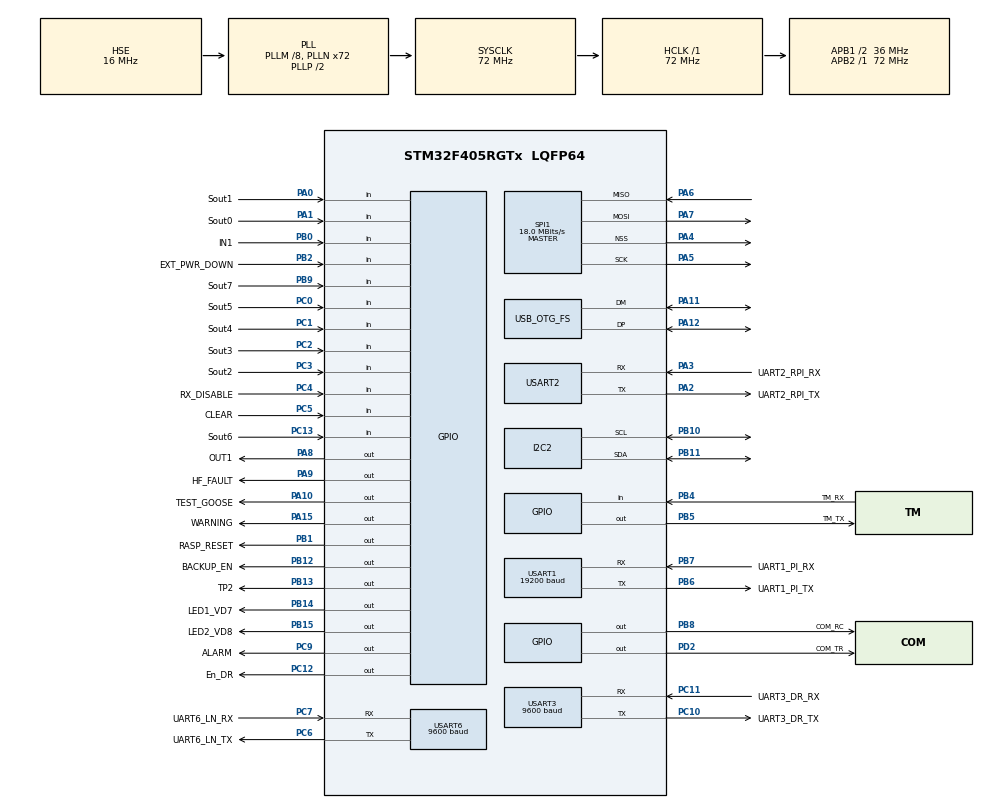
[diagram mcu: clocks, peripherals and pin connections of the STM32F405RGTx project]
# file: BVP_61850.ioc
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I2C2.DualAddressMode=I2C_DUALADDRESS_ENABLE
I2C2.I2C_Mode=I2C_Standard
I2C2.OwnAddress=0x3D
I2C2.OwnAddress2=0x3E
Mcu.Family=STM32F4
Mcu.Name=STM32F405RGTx
Mcu.Package=LQFP64
NVIC.I2C2_ER_IRQn=true\:0\:0\:false\:false\:true\:true\:true
NVIC.I2C2_EV_IRQn=true\:0\:0\:false\:false\:true\:true\:true
NVIC.OTG_FS_IRQn=true\:0\:0\:false\:false\:true\:false\:true
NVIC.PriorityGroup=NVIC_PRIORITYGROUP_4
NVIC.TIM6_DAC_IRQn=true\:0\:0\:false\:false\:true\:true\:true
NVIC.TIM7_IRQn=true\:0\:0\:false\:false\:true\:true\:true
NVIC.USART1_IRQn=true\:0\:0\:false\:false\:true\:true\:true
NVIC.USART2_IRQn=true\:0\:0\:false\:false\:true\:true\:true
NVIC.USART3_IRQn=true\:0\:0\:false\:false\:true\:true\:true
NVIC.USART6_IRQn=true\:0\:0\:false\:false\:true\:true\:true
PA0-WKUP.GPIO_Label=Sout1
PA0-WKUP.GPIO_PuPd=GPIO_PULLUP
PA0-WKUP.Signal=GPIO_Input
PA1.GPIO_Label=Sout0
PA1.GPIO_PuPd=GPIO_PULLUP
PA1.Signal=GPIO_Input
PA10.GPIO_Label=TEST_GOOSE
PA10.Signal=GPIO_Output
PA11.Mode=Device_Only
PA11.Signal=USB_OTG_FS_DM
PA12.Mode=Device_Only
PA12.Signal=USB_OTG_FS_DP
PA13.Mode=Trace_Asynchronous_SW
PA13.Signal=SYS_JTMS-SWDIO
PA14.Mode=Trace_Asynchronous_SW
PA14.Signal=SYS_JTCK-SWCLK
PA15.GPIO_Label=WARNING
PA15.Signal=GPIO_Output
PA2.GPIO_Label=UART2_RPI_TX
PA2.Mode=Asynchronous
PA2.Signal=USART2_TX
PA3.GPIO_Label=UART2_RPI_RX
PA3.Mode=Asynchronous
PA3.Signal=USART2_RX
PA4.Mode=NSS_Signal_Hard_Output
PA4.Signal=SPI1_NSS
PA5.Mode=Full_Duplex_Master
PA5.Signal=SPI1_SCK
PA6.Mode=Full_Duplex_Master
PA6.Signal=SPI1_MISO
PA7.Mode=Full_Duplex_Master
PA7.Signal=SPI1_MOSI
PA8.GPIO_Label=OUT1
PA8.Signal=GPIO_Output
PA9.GPIO_Label=HF_FAULT
PA9.Signal=GPIO_Output
PB0.GPIO_Label=IN1
PB0.Signal=GPIO_Input
PB1.GPIO_Label=RASP_RESET
PB1.PinState=GPIO_PIN_SET
PB1.Signal=GPIO_Output
PB10.Mode=I2C
PB10.Signal=I2C2_SCL
PB11.Mode=I2C
PB11.Signal=I2C2_SDA
PB12.GPIO_Label=BACKUP_EN
PB12.GPIO_Speed=GPIO_SPEED_FREQ_HIGH
PB12.Signal=GPIO_Output
PB13.GPIO_Label=TP2
PB13.Signal=GPIO_Output
PB14.GPIO_Label=LED1_VD7
PB14.Signal=GPIO_Output
PB15.GPIO_Label=LED2_VD8
PB15.GPIO_ModeDefaultOutputPP=GPIO_MODE_OUTPUT_OD
PB15.Signal=GPIO_Output
PB2.GPIO_Label=EXT_PWR_DOWN
PB2.GPIO_PuPd=GPIO_PULLUP
PB2.Signal=GPIO_Input
PB3.Mode=Trace_Asynchronous_SW
PB3.Signal=SYS_JTDO-SWO
PB4.GPIO_Label=TM_RX
PB4.Signal=GPIO_Input
PB5.GPIO_Label=TM_TX
PB5.Signal=GPIO_Output
PB6.GPIO_Label=UART1_PI_TX
PB6.Mode=Asynchronous
PB6.Signal=USART1_TX
PB7.GPIO_Label=UART1_PI_RX
PB7.Mode=Asynchronous
PB7.Signal=USART1_RX
PB8.GPIO_Label=COM_RC
PB8.Signal=GPIO_Output
PB9.GPIO_Label=Sout7
PB9.GPIO_PuPd=GPIO_PULLUP
PB9.Signal=GPIO_Input
PC0.GPIO_Label=Sout5
PC0.GPIO_PuPd=GPIO_PULLUP
PC0.Signal=GPIO_Input
PC1.GPIO_Label=Sout4
PC1.GPIO_PuPd=GPIO_PULLUP
PC1.Signal=GPIO_Input
PC10.GPIO_Label=UART3_DR_TX
PC10.Mode=Asynchronous
PC10.Signal=USART3_TX
PC11.GPIO_Label=UART3_DR_RX
PC11.Mode=Asynchronous
PC11.Signal=USART3_RX
PC12.GPIO_Label=En_DR
PC12.Signal=GPIO_Output
PC13-ANTI_TAMP.GPIO_Label=Sout6
PC13-ANTI_TAMP.GPIO_PuPd=GPIO_PULLUP
PC13-ANTI_TAMP.Signal=GPIO_Input
PC2.GPIO_Label=Sout3
PC2.GPIO_PuPd=GPIO_PULLUP
PC2.Signal=GPIO_Input
PC3.GPIO_Label=Sout2
PC3.GPIO_PuPd=GPIO_PULLUP
PC3.Signal=GPIO_Input
PC4.GPIO_Label=RX_DISABLE
PC4.Signal=GPIO_Input
PC5.GPIO_Label=CLEAR
PC5.Signal=GPIO_Input
PC6.GPIO_Label=UART6_LN_TX
PC6.Mode=Asynchronous
PC6.Signal=USART6_TX
PC7.GPIO_Label=UART6_LN_RX
PC7.Mode=Asynchronous
PC7.Signal=USART6_RX
PC9.GPIO_Label=ALARM
PC9.Signal=GPIO_Output
PD2.GPIO_Label=COM_TR
PD2.Signal=GPIO_Output
PH0-OSC_IN.Mode=HSE-External-Oscillator
PH0-OSC_IN.Signal=RCC_OSC_IN
PH1-OSC_OUT.Mode=HSE-External-Oscillator
PH1-OSC_OUT.Signal=RCC_OSC_OUT
ProjectManager.HeapSize=0x4000
ProjectManager.StackSize=0x4000
ProjectManager.TargetToolchain=SW4STM32
RCC.48MHZClocksFreq_Value=48000000
RCC.AHBFreq_Value=72000000
RCC.APB1CLKDivider=RCC_HCLK_DIV2
RCC.APB1Freq_Value=36000000
RCC.APB1TimFreq_Value=72000000
RCC.APB2Freq_Value=72000000
RCC.APB2TimFreq_Value=72000000
RCC.CortexFreq_Value=72000000
RCC.HCLKFreq_Value=72000000
RCC.HSE_VALUE=16000000
RCC.HSI_VALUE=16000000
RCC.LSE_VALUE=32768
RCC.PLLM=8
RCC.PLLN=72
RCC.PLLQ=3
RCC.SYSCLKFreq_VALUE=72000000
RCC.SYSCLKSource=RCC_SYSCLKSOURCE_PLLCLK
RCC.VCOOutputFreq_Value=144000000
SPI1.BaudRatePrescaler=SPI_BAUDRATEPRESCALER_4
SPI1.CalculateBaudRate=18.0 MBits/s
SPI1.Direction=SPI_DIRECTION_2LINES
SPI1.Mode=SPI_MODE_MASTER
SPI1.VirtualNSS=VM_NSSHARD
SPI1.VirtualType=VM_MASTER
TIM6.AutoReloadPreload=TIM_AUTORELOAD_PRELOAD_ENABLE
TIM6.Period=9
TIM6.Prescaler=7199
TIM7.AutoReloadPreload=TIM_AUTORELOAD_PRELOAD_ENABLE
TIM7.Period=9
TIM7.Prescaler=719
USART1.BaudRate=19200
USART1.StopBits=STOPBITS_2
USART1.VirtualMode=VM_ASYNC
USART2.VirtualMode=VM_ASYNC
USART3.BaudRate=9600
USART3.Parity=PARITY_EVEN
USART3.VirtualMode=VM_ASYNC
USART3.WordLength=WORDLENGTH_9B
USART6.BaudRate=9600
USART6.Parity=PARITY_EVEN
USART6.VirtualMode=VM_ASYNC
USART6.WordLength=WORDLENGTH_9B
USB_DEVICE.CLASS_NAME_FS=CDC
USB_DEVICE.VirtualMode-CDC_FS=Cdc
USB_DEVICE.VirtualModeFS=Cdc_FS
USB_OTG_FS.VirtualMode=Device_Only
VP_IWDG_VS_IWDG.Mode=IWDG_Activate
VP_TIM6_VS_ClockSourceINT.Mode=Enable_Timer
VP_TIM7_VS_ClockSourceINT.Mode=Enable_Timer
VP_USB_DEVICE_VS_USB_DEVICE_CDC_FS.Mode=CDC_FS
board=custom

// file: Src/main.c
/* USER CODE BEGIN Header */
/**
 ******************************************************************************
 * @file           : main.c
 * @brief          : Main program body
 ******************************************************************************
 * @attention
 *
 * <h2><center>&copy; Copyright (c) 2020 STMicroelectronics.
 * All rights reserved.</center></h2>
 *
 * This software component is licensed by ST under Ultimate Liberty license
 * SLA0044, the "License"; You may not use this file except in compliance with
 * the License. You may obtain a copy of the License at:
 *                             www.st.com/SLA0044
 *
 ******************************************************************************
 */
/* USER CODE END Header */
#include "main.h"
#include "usb_device.h"

/* USER CODE BEGIN Includes */
#include "wrapper.hpp"
/* USER CODE END Includes */

I2C_HandleTypeDef hi2c2;

IWDG_HandleTypeDef hiwdg;

SPI_HandleTypeDef hspi1;

TIM_HandleTypeDef htim6;
TIM_HandleTypeDef htim7;

UART_HandleTypeDef huart1;
UART_HandleTypeDef huart2;
UART_HandleTypeDef huart3;
UART_HandleTypeDef huart6;

void SystemClock_Config(void);
static void MX_GPIO_Init(void);
static void MX_IWDG_Init(void);
static void MX_SPI1_Init(void);
static void MX_USART1_UART_Init(void);
static void MX_USART2_UART_Init(void);
static void MX_USART3_UART_Init(void);
static void MX_USART6_UART_Init(void);
static void MX_TIM6_Init(void);
static void MX_I2C2_Init(void);
static void MX_TIM7_Init(void);

int main(void)
{

  /* MCU Configuration--------------------------------------------------------*/

  /* Reset of all peripherals, Initializes the Flash interface and the Systick. */
  HAL_Init();

  /* Configure the system clock */
  SystemClock_Config();

  /* Initialize all configured peripherals */
  MX_GPIO_Init();
  MX_IWDG_Init();
  MX_SPI1_Init();
  MX_USART1_UART_Init();
  MX_USART2_UART_Init();
  MX_USART3_UART_Init();
  MX_USART6_UART_Init();
  MX_TIM6_Init();
  MX_USB_DEVICE_Init();
  MX_I2C2_Init();
  MX_TIM7_Init();
  /* USER CODE BEGIN 2 */

  wrapperMainInit();

  /* USER CODE END 2 */

  /* Infinite loop */
  /* USER CODE BEGIN WHILE */
  HAL_TIM_Base_Start_IT(&htim6);
  HAL_TIM_Base_Start_IT(&htim7);

  while (1) {
    /* USER CODE END WHILE */

    /* USER CODE BEGIN 3 */
    wrapperMainLoop();
  }
  /* USER CODE END 3 */
}

void SystemClock_Config(void)
{
  RCC_OscInitTypeDef RCC_OscInitStruct = {0};
  RCC_ClkInitTypeDef RCC_ClkInitStruct = {0};

  /** Configure the main internal regulator output voltage
  */
  __HAL_RCC_PWR_CLK_ENABLE();
  __HAL_PWR_VOLTAGESCALING_CONFIG(PWR_REGULATOR_VOLTAGE_SCALE1);
  /** Initializes the RCC Oscillators according to the specified parameters
  * in the RCC_OscInitTypeDef structure.
  */
  RCC_OscInitStruct.OscillatorType = RCC_OSCILLATORTYPE_LSI|RCC_OSCILLATORTYPE_HSE;
  RCC_OscInitStruct.HSEState = RCC_HSE_ON;
  RCC_OscInitStruct.LSIState = RCC_LSI_ON;
  RCC_OscInitStruct.PLL.PLLState = RCC_PLL_ON;
  RCC_OscInitStruct.PLL.PLLSource = RCC_PLLSOURCE_HSE;
  RCC_OscInitStruct.PLL.PLLM = 8;
  RCC_OscInitStruct.PLL.PLLN = 72;
  RCC_OscInitStruct.PLL.PLLP = RCC_PLLP_DIV2;
  RCC_OscInitStruct.PLL.PLLQ = 3;
  if (HAL_RCC_OscConfig(&RCC_OscInitStruct) != HAL_OK)
  {
    Error_Handler();
  }
  /** Initializes the CPU, AHB and APB buses clocks
  */
  RCC_ClkInitStruct.ClockType = RCC_CLOCKTYPE_HCLK|RCC_CLOCKTYPE_SYSCLK
                              |RCC_CLOCKTYPE_PCLK1|RCC_CLOCKTYPE_PCLK2;
  RCC_ClkInitStruct.SYSCLKSource = RCC_SYSCLKSOURCE_PLLCLK;
  RCC_ClkInitStruct.AHBCLKDivider = RCC_SYSCLK_DIV1;
  RCC_ClkInitStruct.APB1CLKDivider = RCC_HCLK_DIV2;
  RCC_ClkInitStruct.APB2CLKDivider = RCC_HCLK_DIV1;

  if (HAL_RCC_ClockConfig(&RCC_ClkInitStruct, FLASH_LATENCY_2) != HAL_OK)
  {
    Error_Handler();
  }
}

static void MX_I2C2_Init(void)
{

  hi2c2.Instance = I2C2;
  hi2c2.Init.ClockSpeed = 100000;
  hi2c2.Init.DutyCycle = I2C_DUTYCYCLE_2;
  hi2c2.Init.OwnAddress1 = 122;
  hi2c2.Init.AddressingMode = I2C_ADDRESSINGMODE_7BIT;
  hi2c2.Init.DualAddressMode = I2C_DUALADDRESS_ENABLE;
  hi2c2.Init.OwnAddress2 = 124;
  hi2c2.Init.GeneralCallMode = I2C_GENERALCALL_DISABLE;
  hi2c2.Init.NoStretchMode = I2C_NOSTRETCH_DISABLE;
  if (HAL_I2C_Init(&hi2c2) != HAL_OK)
  {
    Error_Handler();
  }

}

static void MX_IWDG_Init(void)
{

  hiwdg.Instance = IWDG;
  hiwdg.Init.Prescaler = IWDG_PRESCALER_4;
  hiwdg.Init.Reload = 4095;
  if (HAL_IWDG_Init(&hiwdg) != HAL_OK)
  {
    Error_Handler();
  }

}

static void MX_SPI1_Init(void)
{

  /* SPI1 parameter configuration*/
  hspi1.Instance = SPI1;
  hspi1.Init.Mode = SPI_MODE_MASTER;
  hspi1.Init.Direction = SPI_DIRECTION_2LINES;
  hspi1.Init.DataSize = SPI_DATASIZE_8BIT;
  hspi1.Init.CLKPolarity = SPI_POLARITY_LOW;
  hspi1.Init.CLKPhase = SPI_PHASE_1EDGE;
  hspi1.Init.NSS = SPI_NSS_HARD_OUTPUT;
  hspi1.Init.BaudRatePrescaler = SPI_BAUDRATEPRESCALER_4;
  hspi1.Init.FirstBit = SPI_FIRSTBIT_MSB;
  hspi1.Init.TIMode = SPI_TIMODE_DISABLE;
  hspi1.Init.CRCCalculation = SPI_CRCCALCULATION_DISABLE;
  hspi1.Init.CRCPolynomial = 10;
  if (HAL_SPI_Init(&hspi1) != HAL_OK)
  {
    Error_Handler();
  }

}

static void MX_TIM6_Init(void)
{

  TIM_MasterConfigTypeDef sMasterConfig = {0};

  htim6.Instance = TIM6;
  htim6.Init.Prescaler = 7199;
  htim6.Init.CounterMode = TIM_COUNTERMODE_UP;
  htim6.Init.Period = 9;
  htim6.Init.AutoReloadPreload = TIM_AUTORELOAD_PRELOAD_ENABLE;
  if (HAL_TIM_Base_Init(&htim6) != HAL_OK)
  {
    Error_Handler();
  }
  sMasterConfig.MasterOutputTrigger = TIM_TRGO_RESET;
  sMasterConfig.MasterSlaveMode = TIM_MASTERSLAVEMODE_DISABLE;
  if (HAL_TIMEx_MasterConfigSynchronization(&htim6, &sMasterConfig) != HAL_OK)
  {
    Error_Handler();
  }

}

static void MX_TIM7_Init(void)
{

  TIM_MasterConfigTypeDef sMasterConfig = {0};

  htim7.Instance = TIM7;
  htim7.Init.Prescaler = 719;
  htim7.Init.CounterMode = TIM_COUNTERMODE_UP;
  htim7.Init.Period = 9;
  htim7.Init.AutoReloadPreload = TIM_AUTORELOAD_PRELOAD_ENABLE;
  if (HAL_TIM_Base_Init(&htim7) != HAL_OK)
  {
    Error_Handler();
  }
  sMasterConfig.MasterOutputTrigger = TIM_TRGO_RESET;
  sMasterConfig.MasterSlaveMode = TIM_MASTERSLAVEMODE_DISABLE;
  if (HAL_TIMEx_MasterConfigSynchronization(&htim7, &sMasterConfig) != HAL_OK)
  {
    Error_Handler();
  }

}

static void MX_USART1_UART_Init(void)
{

  huart1.Instance = USART1;
  huart1.Init.BaudRate = 19200;
  huart1.Init.WordLength = UART_WORDLENGTH_8B;
  huart1.Init.StopBits = UART_STOPBITS_2;
  huart1.Init.Parity = UART_PARITY_NONE;
  huart1.Init.Mode = UART_MODE_TX_RX;
  huart1.Init.HwFlowCtl = UART_HWCONTROL_NONE;
  huart1.Init.OverSampling = UART_OVERSAMPLING_16;
  if (HAL_UART_Init(&huart1) != HAL_OK)
  {
    Error_Handler();
  }

}

static void MX_USART2_UART_Init(void)
{

  huart2.Instance = USART2;
  huart2.Init.BaudRate = 115200;
  huart2.Init.WordLength = UART_WORDLENGTH_8B;
  huart2.Init.StopBits = UART_STOPBITS_1;
  huart2.Init.Parity = UART_PARITY_NONE;
  huart2.Init.Mode = UART_MODE_TX_RX;
  huart2.Init.HwFlowCtl = UART_HWCONTROL_NONE;
  huart2.Init.OverSampling = UART_OVERSAMPLING_16;
  if (HAL_UART_Init(&huart2) != HAL_OK)
  {
    Error_Handler();
  }

}

static void MX_USART3_UART_Init(void)
{

  huart3.Instance = USART3;
  huart3.Init.BaudRate = 9600;
  huart3.Init.WordLength = UART_WORDLENGTH_9B;
  huart3.Init.StopBits = UART_STOPBITS_1;
  huart3.Init.Parity = UART_PARITY_EVEN;
  huart3.Init.Mode = UART_MODE_TX_RX;
  huart3.Init.HwFlowCtl = UART_HWCONTROL_NONE;
  huart3.Init.OverSampling = UART_OVERSAMPLING_16;
  if (HAL_UART_Init(&huart3) != HAL_OK)
  {
    Error_Handler();
  }

}

static void MX_USART6_UART_Init(void)
{

  huart6.Instance = USART6;
  huart6.Init.BaudRate = 9600;
  huart6.Init.WordLength = UART_WORDLENGTH_9B;
  huart6.Init.StopBits = UART_STOPBITS_1;
  huart6.Init.Parity = UART_PARITY_EVEN;
  huart6.Init.Mode = UART_MODE_TX_RX;
  huart6.Init.HwFlowCtl = UART_HWCONTROL_NONE;
  huart6.Init.OverSampling = UART_OVERSAMPLING_16;
  if (HAL_UART_Init(&huart6) != HAL_OK)
  {
    Error_Handler();
  }

}

static void MX_GPIO_Init(void)
{
  GPIO_InitTypeDef GPIO_InitStruct = {0};

  /* GPIO Ports Clock Enable */
  __HAL_RCC_GPIOC_CLK_ENABLE();
  __HAL_RCC_GPIOH_CLK_ENABLE();
  __HAL_RCC_GPIOA_CLK_ENABLE();
  __HAL_RCC_GPIOB_CLK_ENABLE();
  __HAL_RCC_GPIOD_CLK_ENABLE();

  /*Configure GPIO pin Output Level */
  HAL_GPIO_WritePin(RASP_RESET_GPIO_Port, RASP_RESET_Pin, GPIO_PIN_SET);

  /*Configure GPIO pin Output Level */
  HAL_GPIO_WritePin(GPIOB, BACKUP_EN_Pin|TP2_Pin|LED1_VD7_Pin|LED2_VD8_Pin
                          |TM_TX_Pin|COM_RC_Pin, GPIO_PIN_RESET);

  /*Configure GPIO pin Output Level */
  HAL_GPIO_WritePin(GPIOC, ALARM_Pin|En_DR_Pin, GPIO_PIN_RESET);

  /*Configure GPIO pin Output Level */
  HAL_GPIO_WritePin(GPIOA, OUT1_Pin|HF_FAULT_Pin|TEST_GOOSE_Pin|WARNING_Pin, GPIO_PIN_RESET);

  /*Configure GPIO pin Output Level */
  HAL_GPIO_WritePin(COM_TR_GPIO_Port, COM_TR_Pin, GPIO_PIN_RESET);

  /*Configure GPIO pins : Sout6_Pin Sout5_Pin Sout4_Pin Sout3_Pin
                           Sout2_Pin */
  GPIO_InitStruct.Pin = Sout6_Pin|Sout5_Pin|Sout4_Pin|Sout3_Pin
                          |Sout2_Pin;
  GPIO_InitStruct.Mode = GPIO_MODE_INPUT;
  GPIO_InitStruct.Pull = GPIO_PULLUP;
  HAL_GPIO_Init(GPIOC, &GPIO_InitStruct);

  /*Configure GPIO pins : Sout1_Pin Sout0_Pin */
  GPIO_InitStruct.Pin = Sout1_Pin|Sout0_Pin;
  GPIO_InitStruct.Mode = GPIO_MODE_INPUT;
  GPIO_InitStruct.Pull = GPIO_PULLUP;
  HAL_GPIO_Init(GPIOA, &GPIO_InitStruct);

  /*Configure GPIO pins : RX_DISABLE_Pin CLEAR_Pin */
  GPIO_InitStruct.Pin = RX_DISABLE_Pin|CLEAR_Pin;
  GPIO_InitStruct.Mode = GPIO_MODE_INPUT;
  GPIO_InitStruct.Pull = GPIO_NOPULL;
  HAL_GPIO_Init(GPIOC, &GPIO_InitStruct);

  /*Configure GPIO pins : IN1_Pin TM_RX_Pin */
  GPIO_InitStruct.Pin = IN1_Pin|TM_RX_Pin;
  GPIO_InitStruct.Mode = GPIO_MODE_INPUT;
  GPIO_InitStruct.Pull = GPIO_NOPULL;
  HAL_GPIO_Init(GPIOB, &GPIO_InitStruct);

  /*Configure GPIO pins : RASP_RESET_Pin TP2_Pin LED1_VD7_Pin TM_TX_Pin
                           COM_RC_Pin */
  GPIO_InitStruct.Pin = RASP_RESET_Pin|TP2_Pin|LED1_VD7_Pin|TM_TX_Pin
                          |COM_RC_Pin;
  GPIO_InitStruct.Mode = GPIO_MODE_OUTPUT_PP;
  GPIO_InitStruct.Pull = GPIO_NOPULL;
  GPIO_InitStruct.Speed = GPIO_SPEED_FREQ_LOW;
  HAL_GPIO_Init(GPIOB, &GPIO_InitStruct);

  /*Configure GPIO pins : EXT_PWR_DOWN_Pin Sout7_Pin */
  GPIO_InitStruct.Pin = EXT_PWR_DOWN_Pin|Sout7_Pin;
  GPIO_InitStruct.Mode = GPIO_MODE_INPUT;
  GPIO_InitStruct.Pull = GPIO_PULLUP;
  HAL_GPIO_Init(GPIOB, &GPIO_InitStruct);

  /*Configure GPIO pin : BACKUP_EN_Pin */
  GPIO_InitStruct.Pin = BACKUP_EN_Pin;
  GPIO_InitStruct.Mode = GPIO_MODE_OUTPUT_PP;
  GPIO_InitStruct.Pull = GPIO_NOPULL;
  GPIO_InitStruct.Speed = GPIO_SPEED_FREQ_HIGH;
  HAL_GPIO_Init(BACKUP_EN_GPIO_Port, &GPIO_InitStruct);

  /*Configure GPIO pin : LED2_VD8_Pin */
  GPIO_InitStruct.Pin = LED2_VD8_Pin;
  GPIO_InitStruct.Mode = GPIO_MODE_OUTPUT_OD;
  GPIO_InitStruct.Pull = GPIO_NOPULL;
  GPIO_InitStruct.Speed = GPIO_SPEED_FREQ_LOW;
  HAL_GPIO_Init(LED2_VD8_GPIO_Port, &GPIO_InitStruct);

  /*Configure GPIO pins : ALARM_Pin En_DR_Pin */
  GPIO_InitStruct.Pin = ALARM_Pin|En_DR_Pin;
  GPIO_InitStruct.Mode = GPIO_MODE_OUTPUT_PP;
  GPIO_InitStruct.Pull = GPIO_NOPULL;
  GPIO_InitStruct.Speed = GPIO_SPEED_FREQ_LOW;
  HAL_GPIO_Init(GPIOC, &GPIO_InitStruct);

  /*Configure GPIO pins : OUT1_Pin HF_FAULT_Pin TEST_GOOSE_Pin WARNING_Pin */
  GPIO_InitStruct.Pin = OUT1_Pin|HF_FAULT_Pin|TEST_GOOSE_Pin|WARNING_Pin;
  GPIO_InitStruct.Mode = GPIO_MODE_OUTPUT_PP;
  GPIO_InitStruct.Pull = GPIO_NOPULL;
  GPIO_InitStruct.Speed = GPIO_SPEED_FREQ_LOW;
  HAL_GPIO_Init(GPIOA, &GPIO_InitStruct);

  /*Configure GPIO pin : COM_TR_Pin */
  GPIO_InitStruct.Pin = COM_TR_Pin;
  GPIO_InitStruct.Mode = GPIO_MODE_OUTPUT_PP;
  GPIO_InitStruct.Pull = GPIO_NOPULL;
  GPIO_InitStruct.Speed = GPIO_SPEED_FREQ_LOW;
  HAL_GPIO_Init(COM_TR_GPIO_Port, &GPIO_InitStruct);

}

void Error_Handler(void)
{
  /* USER CODE BEGIN Error_Handler_Debug */
  /* User can add his own implementation to report the HAL error return state */
  printf("Error_Handler()\n");
  /* USER CODE END Error_Handler_Debug */
}

#ifdef  USE_FULL_ASSERT
/**
  * @brief  Reports the name of the source file and the source line number
  *         where the assert_param error has occurred.
  * @param  file: pointer to the source file name
  * @param  line: assert_param error line source number
  * @retval None
  */
void assert_failed(uint8_t *file, uint32_t line)
{
  /* USER CODE BEGIN 6 */
  /* User can add his own implementation to report the file name and line number,
	 tex: printf("Wrong parameters value: file %s on line %d\r\n", file, line) */
  printf("assert_failed() : %s (%ld)\n", file, line);
  while(1);
  /* USER CODE END 6 */
}
#endif /* USE_FULL_ASSERT */

/************************ (C) COPYRIGHT STMicroelectronics *****END OF FILE****/
